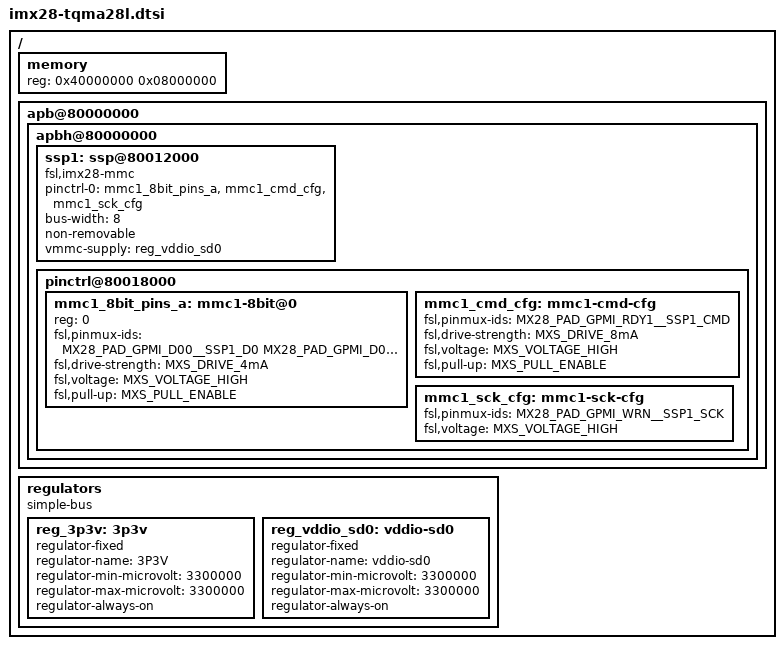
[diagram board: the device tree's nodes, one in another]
/*
 * Copyright 2012 Freescale Semiconductor, Inc.
 *
 * The code contained herein is licensed under the GNU General Public
 * License. You may obtain a copy of the GNU General Public License
 * Version 2 or later at the following locations:
 *
 * http://www.opensource.org/licenses/gpl-license.html
 * http://www.gnu.org/copyleft/gpl.html
 */

#include "imx28.dtsi"

/ {
	memory {
		reg = <0x40000000 0x08000000>;
	};

	apb@80000000 {
		apbh@80000000 {
			/* Attention: TQMa28L has e-MMC on SSP1 */
			ssp1: ssp@80012000 {
				compatible = "fsl,imx28-mmc";
				pinctrl-names = "default";
				pinctrl-0 = <&mmc1_8bit_pins_a
						&mmc1_cmd_cfg
						&mmc1_sck_cfg>;
				bus-width = <8>;
				non-removable;
				vmmc-supply = <&reg_vddio_sd0>;
				status = "okay";
			};

			pinctrl@80018000 {
				mmc1_8bit_pins_a: mmc1-8bit@0 {
					reg = <0>;
					fsl,pinmux-ids = <
						MX28_PAD_GPMI_D00__SSP1_D0
						MX28_PAD_GPMI_D01__SSP1_D1
						MX28_PAD_GPMI_D02__SSP1_D2
						MX28_PAD_GPMI_D03__SSP1_D3
						MX28_PAD_GPMI_D04__SSP1_D4
						MX28_PAD_GPMI_D05__SSP1_D5
						MX28_PAD_GPMI_D06__SSP1_D6
						MX28_PAD_GPMI_D07__SSP1_D7
					>;
					fsl,drive-strength = <MXS_DRIVE_4mA>;
					fsl,voltage = <MXS_VOLTAGE_HIGH>;
					fsl,pull-up = <MXS_PULL_ENABLE>;
				};

				mmc1_cmd_cfg: mmc1-cmd-cfg {
					fsl,pinmux-ids = <
						MX28_PAD_GPMI_RDY1__SSP1_CMD
					>;
					fsl,drive-strength = <MXS_DRIVE_8mA>;
					fsl,voltage = <MXS_VOLTAGE_HIGH>;
					fsl,pull-up = <MXS_PULL_ENABLE>;
				};

				mmc1_sck_cfg: mmc1-sck-cfg {
					fsl,pinmux-ids = <
						MX28_PAD_GPMI_WRN__SSP1_SCK
					>;
					fsl,voltage = <MXS_VOLTAGE_HIGH>;
				};
			};
		};
	};

	regulators {
		compatible = "simple-bus";

		reg_3p3v: 3p3v {
			compatible = "regulator-fixed";
			regulator-name = "3P3V";
			regulator-min-microvolt = <3300000>;
			regulator-max-microvolt = <3300000>;
			regulator-always-on;
		};

		reg_vddio_sd0: vddio-sd0 {
			compatible = "regulator-fixed";
			regulator-name = "vddio-sd0";
			regulator-min-microvolt = <3300000>;
			regulator-max-microvolt = <3300000>;
			regulator-always-on;
		};
	};
};
